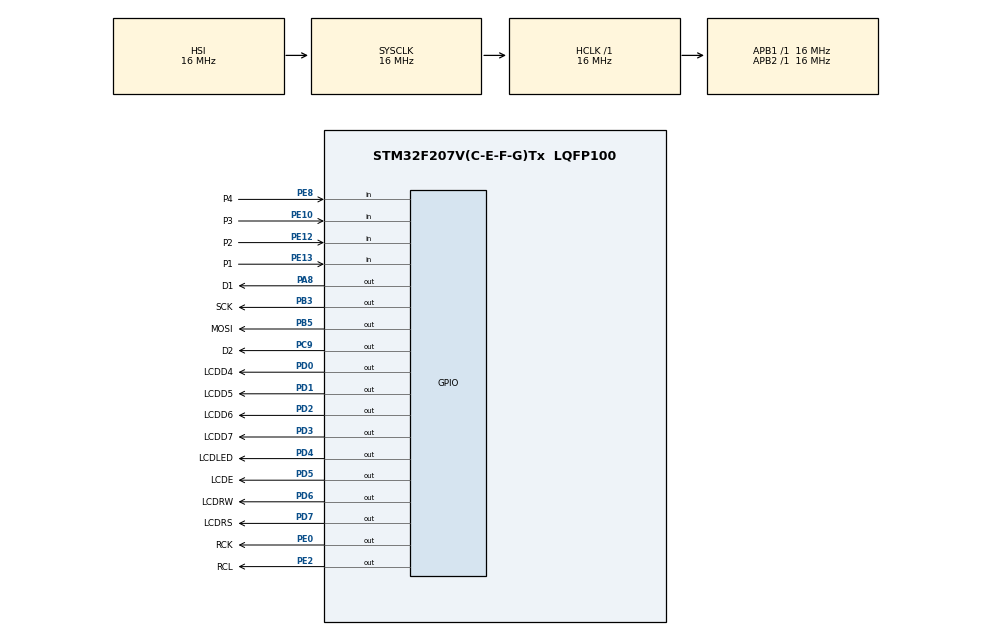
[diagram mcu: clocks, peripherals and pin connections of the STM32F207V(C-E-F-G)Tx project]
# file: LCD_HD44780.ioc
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Mcu.Family=STM32F2
Mcu.Name=STM32F207V(C-E-F-G)Tx
Mcu.Package=LQFP100
NVIC.PriorityGroup=NVIC_PRIORITYGROUP_4
PA13.Mode=Serial_Wire
PA13.Signal=SYS_JTMS-SWDIO
PA14.Mode=Serial_Wire
PA14.Signal=SYS_JTCK-SWCLK
PA8.GPIO_Label=D1
PA8.Signal=GPIO_Output
PB3.GPIO_Label=SCK
PB3.Signal=GPIO_Output
PB5.GPIO_Label=MOSI
PB5.Signal=GPIO_Output
PC9.GPIO_Label=D2
PC9.Signal=GPIO_Output
PD0.GPIO_Label=LCDD4
PD0.Signal=GPIO_Output
PD1.GPIO_Label=LCDD5
PD1.Signal=GPIO_Output
PD2.GPIO_Label=LCDD6
PD2.Signal=GPIO_Output
PD3.GPIO_Label=LCDD7
PD3.Signal=GPIO_Output
PD4.GPIO_Label=LCDLED
PD4.Signal=GPIO_Output
PD5.GPIO_Label=LCDE
PD5.Signal=GPIO_Output
PD6.GPIO_Label=LCDRW
PD6.Signal=GPIO_Output
PD7.GPIO_Label=LCDRS
PD7.Signal=GPIO_Output
PE0.GPIO_Label=RCK
PE0.Signal=GPIO_Output
PE10.GPIO_Label=P3
PE10.GPIO_PuPd=GPIO_PULLUP
PE10.Signal=GPIO_Input
PE12.GPIO_Label=P2
PE12.GPIO_PuPd=GPIO_PULLUP
PE12.Signal=GPIO_Input
PE13.GPIO_Label=P1
PE13.GPIO_PuPd=GPIO_PULLUP
PE13.Signal=GPIO_Input
PE2.GPIO_Label=RCL
PE2.Signal=GPIO_Output
PE8.GPIO_Label=P4
PE8.GPIO_PuPd=GPIO_PULLUP
PE8.Signal=GPIO_Input
ProjectManager.HeapSize=0x200
ProjectManager.StackSize=0x400
ProjectManager.TargetToolchain=MDK-ARM V5.32
RCC.48MHZClocksFreq_Value=48000000
RCC.AHBFreq_Value=16000000
RCC.APB1Freq_Value=16000000
RCC.APB2Freq_Value=16000000
RCC.CortexFreq_Value=16000000
RCC.HSE_VALUE=25000000
RCC.HSI_VALUE=16000000
RCC.LSE_VALUE=32768
RCC.SYSCLKFreq_VALUE=16000000
RCC.VCOOutputFreq_Value=192000000
board=custom

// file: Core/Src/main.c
/* USER CODE BEGIN Header */
/**
  ******************************************************************************
  * @file           : main.c
  * @brief          : Main program body
  ******************************************************************************
  * @attention
  *
  * Copyright (c) 2025 STMicroelectronics.
  * All rights reserved.
  *
  * This software is licensed under terms that can be found in the LICENSE file
  * in the root directory of this software component.
  * If no LICENSE file comes with this software, it is provided AS-IS.
  *
  ******************************************************************************
  */
/* USER CODE END Header */
#include "main.h"

/* USER CODE BEGIN Includes */
#include "myLED.h"
#include <stdio.h>
#include <myLCD.h>

/* USER CODE END Includes */

void SystemClock_Config(void);
static void MX_GPIO_Init(void);

int main(void)
{

  /* MCU Configuration--------------------------------------------------------*/

  /* Reset of all peripherals, Initializes the Flash interface and the Systick. */
  HAL_Init();

  /* Configure the system clock */
  SystemClock_Config();

  /* Initialize all configured peripherals */
  MX_GPIO_Init();
  /* USER CODE BEGIN 2 */
	LCD_Init();
  /* USER CODE END 2 */

  /* Infinite loop */
  while (1)
  {
		LCD_GotoXY(0, 0);
		LCD_PutString((uint8_t *)"Vo Hong Quan");
		LCD_GotoXY(0, 1);
		LCD_PutString((uint8_t *)"22134012");
  }
}

void SystemClock_Config(void)
{
  RCC_OscInitTypeDef RCC_OscInitStruct = {0};
  RCC_ClkInitTypeDef RCC_ClkInitStruct = {0};

  /** Initializes the RCC Oscillators according to the specified parameters
  * in the RCC_OscInitTypeDef structure.
  */
  RCC_OscInitStruct.OscillatorType = RCC_OSCILLATORTYPE_HSI;
  RCC_OscInitStruct.HSIState = RCC_HSI_ON;
  RCC_OscInitStruct.HSICalibrationValue = RCC_HSICALIBRATION_DEFAULT;
  RCC_OscInitStruct.PLL.PLLState = RCC_PLL_NONE;
  if (HAL_RCC_OscConfig(&RCC_OscInitStruct) != HAL_OK)
  {
    Error_Handler();
  }

  /** Initializes the CPU, AHB and APB buses clocks
  */
  RCC_ClkInitStruct.ClockType = RCC_CLOCKTYPE_HCLK|RCC_CLOCKTYPE_SYSCLK
                              |RCC_CLOCKTYPE_PCLK1|RCC_CLOCKTYPE_PCLK2;
  RCC_ClkInitStruct.SYSCLKSource = RCC_SYSCLKSOURCE_HSI;
  RCC_ClkInitStruct.AHBCLKDivider = RCC_SYSCLK_DIV1;
  RCC_ClkInitStruct.APB1CLKDivider = RCC_HCLK_DIV1;
  RCC_ClkInitStruct.APB2CLKDivider = RCC_HCLK_DIV1;

  if (HAL_RCC_ClockConfig(&RCC_ClkInitStruct, FLASH_LATENCY_0) != HAL_OK)
  {
    Error_Handler();
  }
}

static void MX_GPIO_Init(void)
{
  GPIO_InitTypeDef GPIO_InitStruct = {0};

  /* GPIO Ports Clock Enable */
  __HAL_RCC_GPIOE_CLK_ENABLE();
  __HAL_RCC_GPIOC_CLK_ENABLE();
  __HAL_RCC_GPIOA_CLK_ENABLE();
  __HAL_RCC_GPIOD_CLK_ENABLE();
  __HAL_RCC_GPIOB_CLK_ENABLE();

  /*Configure GPIO pin Output Level */
  HAL_GPIO_WritePin(GPIOE, RCL_Pin|RCK_Pin, GPIO_PIN_RESET);

  /*Configure GPIO pin Output Level */
  HAL_GPIO_WritePin(D2_GPIO_Port, D2_Pin, GPIO_PIN_RESET);

  /*Configure GPIO pin Output Level */
  HAL_GPIO_WritePin(D1_GPIO_Port, D1_Pin, GPIO_PIN_RESET);

  /*Configure GPIO pin Output Level */
  HAL_GPIO_WritePin(GPIOD, LCDD4_Pin|LCDD5_Pin|LCDD6_Pin|LCDD7_Pin
                          |LCDLED_Pin|LCDE_Pin|LCDRW_Pin|LCDRS_Pin, GPIO_PIN_RESET);

  /*Configure GPIO pin Output Level */
  HAL_GPIO_WritePin(GPIOB, SCK_Pin|MOSI_Pin, GPIO_PIN_RESET);

  /*Configure GPIO pins : RCL_Pin RCK_Pin */
  GPIO_InitStruct.Pin = RCL_Pin|RCK_Pin;
  GPIO_InitStruct.Mode = GPIO_MODE_OUTPUT_PP;
  GPIO_InitStruct.Pull = GPIO_NOPULL;
  GPIO_InitStruct.Speed = GPIO_SPEED_FREQ_LOW;
  HAL_GPIO_Init(GPIOE, &GPIO_InitStruct);

  /*Configure GPIO pins : P4_Pin P3_Pin P2_Pin P1_Pin */
  GPIO_InitStruct.Pin = P4_Pin|P3_Pin|P2_Pin|P1_Pin;
  GPIO_InitStruct.Mode = GPIO_MODE_INPUT;
  GPIO_InitStruct.Pull = GPIO_PULLUP;
  HAL_GPIO_Init(GPIOE, &GPIO_InitStruct);

  /*Configure GPIO pin : D2_Pin */
  GPIO_InitStruct.Pin = D2_Pin;
  GPIO_InitStruct.Mode = GPIO_MODE_OUTPUT_PP;
  GPIO_InitStruct.Pull = GPIO_NOPULL;
  GPIO_InitStruct.Speed = GPIO_SPEED_FREQ_LOW;
  HAL_GPIO_Init(D2_GPIO_Port, &GPIO_InitStruct);

  /*Configure GPIO pin : D1_Pin */
  GPIO_InitStruct.Pin = D1_Pin;
  GPIO_InitStruct.Mode = GPIO_MODE_OUTPUT_PP;
  GPIO_InitStruct.Pull = GPIO_NOPULL;
  GPIO_InitStruct.Speed = GPIO_SPEED_FREQ_LOW;
  HAL_GPIO_Init(D1_GPIO_Port, &GPIO_InitStruct);

  /*Configure GPIO pins : LCDD4_Pin LCDD5_Pin LCDD6_Pin LCDD7_Pin
                           LCDLED_Pin LCDE_Pin LCDRW_Pin LCDRS_Pin */
  GPIO_InitStruct.Pin = LCDD4_Pin|LCDD5_Pin|LCDD6_Pin|LCDD7_Pin
                          |LCDLED_Pin|LCDE_Pin|LCDRW_Pin|LCDRS_Pin;
  GPIO_InitStruct.Mode = GPIO_MODE_OUTPUT_PP;
  GPIO_InitStruct.Pull = GPIO_NOPULL;
  GPIO_InitStruct.Speed = GPIO_SPEED_FREQ_LOW;
  HAL_GPIO_Init(GPIOD, &GPIO_InitStruct);

  /*Configure GPIO pins : SCK_Pin MOSI_Pin */
  GPIO_InitStruct.Pin = SCK_Pin|MOSI_Pin;
  GPIO_InitStruct.Mode = GPIO_MODE_OUTPUT_PP;
  GPIO_InitStruct.Pull = GPIO_NOPULL;
  GPIO_InitStruct.Speed = GPIO_SPEED_FREQ_LOW;
  HAL_GPIO_Init(GPIOB, &GPIO_InitStruct);

}

void Error_Handler(void)
{
  __disable_irq();
  while (1)
  {
  }
}
